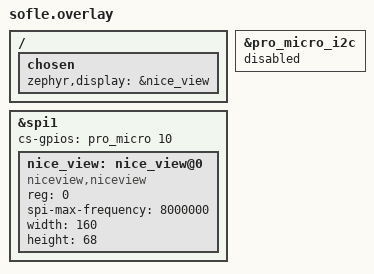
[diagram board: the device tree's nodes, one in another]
/* config/sofle.overlay */

&pro_micro_i2c {
    status = "disabled";
};

&spi1 {
    status = "okay";
    cs-gpios = <&pro_micro 10 GPIO_ACTIVE_HIGH>;

    nice_view: nice_view@0 {
        compatible = "niceview,niceview";
        reg = <0>;
        spi-max-frequency = <8000000>;
        /* 화면 크기 정보 추가 (에러 해결 핵심) */
        width = <160>;
        height = <68>;
    };
};

/ {
    chosen {
        zephyr,display = &nice_view;
    };
};
